# RZN2L register map
Vendor: Renesas Electronics Corporation; Series: RZN; File version: 1.30.01
CPU: other r0p0, little endian, MPU, no FPU, VTOR, 4 interrupt priority bits, 624 interrupts
Registers are 32-bit, read-write, reset 0x0 unless marked. A register's access mark holds for its fields unless they carry their own. Offsets are from the block's base; [hi:lo] are bit positions; {n}, {i} and the like mark numbered series; 'fields as' and 'values as' point back to an identical list.

## XSPI0 — xSPI
Base 0x80220000
Same registers: XSPI1 0x80221000
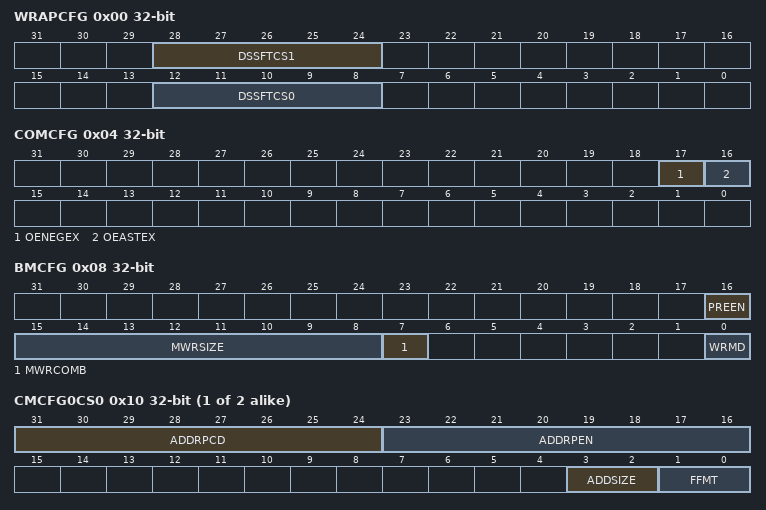
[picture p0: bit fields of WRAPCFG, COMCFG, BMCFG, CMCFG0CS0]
0x00 WRAPCFG — xSPI Wrapper Configuration Register
  [28:24] DSSFTCS1 — DS shift for slave1
  [12:8] DSSFTCS0 — DS shift for slave0
0x04 COMCFG — xSPI Common Configuration Register
  [17] OENEGEX — Output Enable Negating extension
    0=No extend 1 cycle Output enable; 1=Extend 1 cycle Output enable
  [16] OEASTEX — Output Enable Asserting extension
    values as OENEGEX
0x08 BMCFG — xSPI Bridge Map Configuration Register
  [16] PREEN — Prefetch enable
    0=Disable prefetch function; 1=Enable prefetch function
  [15:8] MWRSIZE — Memory Write Size
  [7] MWRCOMB — Memory Write Combination mode
    0=Disable combination mode; 1=Enable combination mode
  [0] WRMD — AHB Write Response mode
    0=Return response after storing to Internal Write Buffer; 1=Return response after issuing write transaction to xSPI bus
{0x10+0x10*i} CMCFG0CS{i} (i=0..1) — xSPI Command Map Configuration Register 0 CSn
  [31:24] ADDRPCD — Address Replace Code
  [23:16] ADDRPEN — Address Replace Enable
    0=No replacement (xSPI frame address field is same as AHB address); 1=Replacement
  [3:2] ADDSIZE — Address size
    0=1 byte (256-byte address space); 1=2 bytes (64 KB address space); 2=3 bytes (16 MB address space); 3=4 bytes (4 GB address space)
  [1:0] FFMT — Frame format
    0=Normal format: Command 1 byte, Address ADDSIZE, Data to AHB transaction; 1=8D-8D-8D profile 1.0 format: Command 2 bytes, Address ADDSIZE, Data to AHB transaction; 2=8D-8D-8D profile 2.0 Command Modifier format: Command & Modifier 6 bytes, Data to AHB transaction; 3=8D-8D-8D profile 2.0 Commands with Extended Command Modifier format: Command & Modifier 6 bytes, Data to AHB transaction
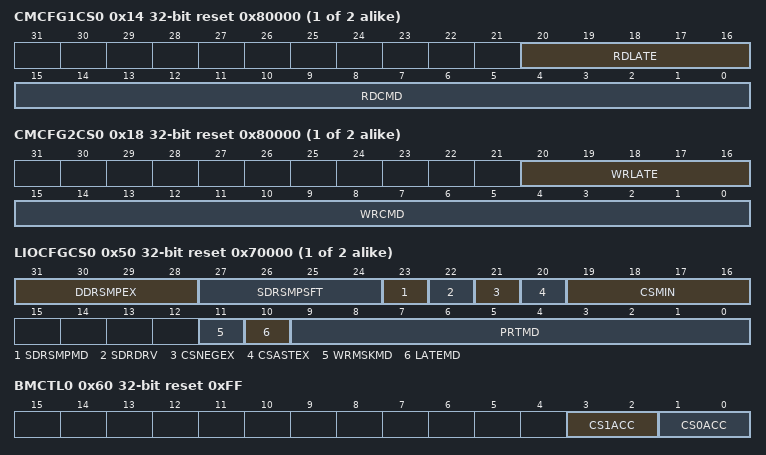
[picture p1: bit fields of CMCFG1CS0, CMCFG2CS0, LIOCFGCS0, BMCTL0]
{0x14+0x10*i} CMCFG1CS{i} (i=0..1) reset 0x80000 — xSPI Command Map Configuration Register 1 CSn
  [20:16] RDLATE — Read latency cycle
  [15:0] RDCMD — Read command
{0x18+0x10*i} CMCFG2CS{i} (i=0..1) reset 0x80000 — xSPI Command Map Configuration Register 2 CSn
  [20:16] WRLATE — Write latency cycle
  [15:0] WRCMD — Write command
{0x50+4i} LIOCFGCS{i} (i=0..1) reset 0x70000 — xSPI Link I/O Configuration Register CSn
  [31:28] DDRSMPEX — DDR sampling window extend
  [27:24] SDRSMPSFT — SDR Sampling window shift
  [23] SDRSMPMD — SDR Sampling mode
    0=Samples data input at falling-edge; 1=Samples data input at rising-edge
  [22] SDRDRV — SDR driving timing
    0=Drive at 1/2 cycle before CK rising-edge; 1=Drive at CK rising-edge
  [21] CSNEGEX — CS negating extension
    0=No extension; 1=Extend 1 cycle
  [20] CSASTEX — CS asserting extension
    0=No extension; 1=Extend 1 cycle
  [19:16] CSMIN — CS minimum idle term
  [11] WRMSKMD — Write mask mode
    0=Write mask disable; 1=Write mask enable
  [10] LATEMD — Latency mode
  [9:0] PRTMD — Protocol mode
    0=1S-1S-1S; 0x3B2=4S-4D-4D; 0x3FF=8D-8D-8D; 72=1S-2S-2S; 73=2S-2S-2S; 144=1S-4S-4S; 146=4S-4S-4S; other=Others (Setting prohibited)
0x60 BMCTL0 reset 0xFF — xSPI Bridge Map Control Register 0
  [3:2] CS1ACC — AHB channel to slave1 memory area access enable
    0=Read/Write disable; 1=Read enable, Write disable; 2=Read disable, Write enable; 3=Read/Write enable
  [1:0] CS0ACC — AHB channel to slave0 memory area access enable
    values as CS1ACC
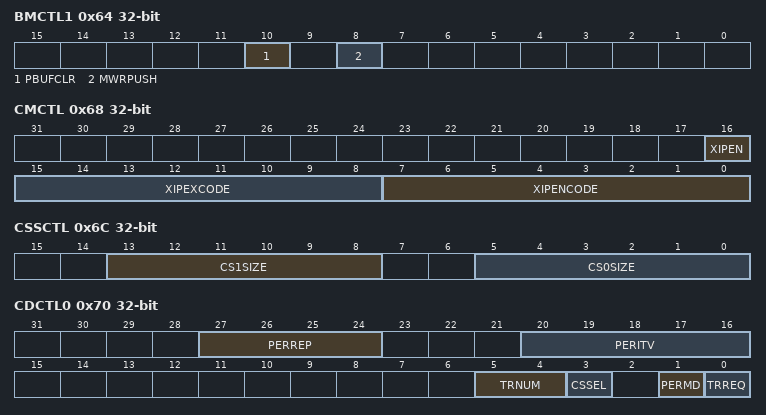
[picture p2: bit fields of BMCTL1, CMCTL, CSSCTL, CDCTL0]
0x64 BMCTL1 wo — xSPI Bridge Map Control Register 1
  [10] PBUFCLR — Prefetch Buffer clear
    0=No command; 1=Clear request
  [8] MWRPUSH — Memory Write Data Push
    0=No command; 1=Push request
0x68 CMCTL — xSPI Command Map Control Register
  [16] XIPEN — XiP mode enable
    0=Disable XiP mode; 1=Enable XiP mode
  [15:8] XIPEXCODE — XiP mode exit code
  [7:0] XIPENCODE — XiP mode enter code
0x6C CSSCTL — xSPI CS Size Control Register
  [13:8] CS1SIZE — CS1 (slave1) size
    0=1 MB; 1=2 MB; 3=4 MB; 7=8 MB; 15=16 MB; 31=32 MB; 63=64 MB; other=Others (Setting prohibited)
  [5:0] CS0SIZE — CS0 (slave0) size
    values as CS1SIZE
0x70 CDCTL0 — xSPI Command Manual Control Register 0
  [27:24] PERREP — Periodic transaction repeat
  [20:16] PERITV — Periodic transaction interval
  [5:4] TRNUM — Transaction number
    0=Issue 1 command (using command buffer 0); 1=Issue 2 commands (using command buffer 0-1); 2=Issue 3 commands (using command buffer 0-2); 3=Issue 4 commands (using command buffer 0-3)
  [3] CSSEL — Chip select
    0=CS0; 1=CS1
  [1] PERMD — Periodic mode
    0=Direct manual-command mode; 1=Periodic manual-command mode
  [0] TRREQ — Transaction request
    0=No transaction; 1=Request transaction
0x74 CDCTL1 — xSPI Command Manual Control Register 1
  [31:0] PEREXP — Periodic transaction expected value
0x78 CDCTL2 — xSPI Command Manual Control Register 2
  [31:0] PERMSK — Periodic transaction masked value
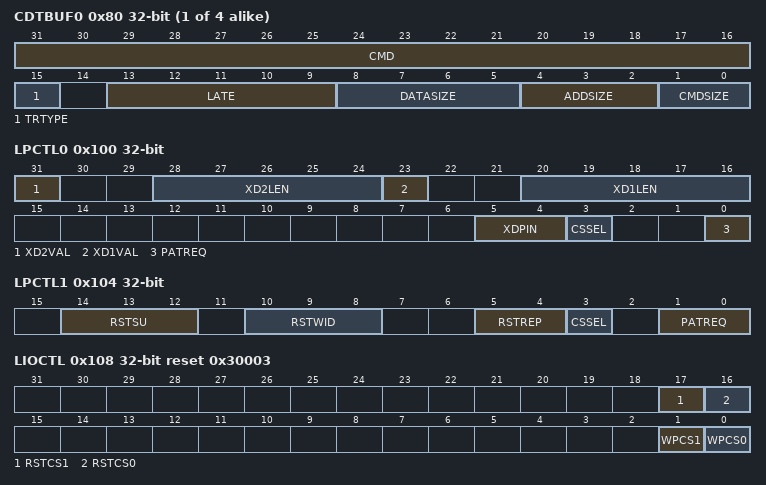
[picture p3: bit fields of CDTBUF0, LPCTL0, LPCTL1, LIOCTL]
{0x80+0x10*i} CDTBUF{i} (i=0..3) — xSPI Command Manual Type Buf {i}
  [31:16] CMD — Command (1-2 bytes)
  [15] TRTYPE — Transaction Type
    0=Read transaction (Readout data from slave device); 1=Not read transaction
  [13:9] LATE — Latency cycle
  [8:5] DATASIZE — Write/Read Data Size
  [4:2] ADDSIZE — Address size
    0=0 bytes (No address phase); 1=1 byte; 2=2 bytes; 3=3 bytes; 4=4 bytes; other=Others (Setting prohibited)
  [1:0] CMDSIZE — Command Size
    0=0 bytes (No command phase); 1=1 byte; 2=2 bytes; other=Others (Setting prohibited)
{0x84+0x10*i} CDABUF{i} (i=0..3) — xSPI Command Manual Address Buf {i}
  [31:0] ADD — Address
{0x88+0x10*i} CDD0BUF{i} (i=0..3) — xSPI Command Manual Data 0 Buf {i}
  [31:0] DATA — Write/Read Data
{0x8C+0x10*i} CDD1BUF{i} (i=0..3) — xSPI Command Manual Data 1 Buf {i}
  [31:0] DATA — Write/Read Data
0x100 LPCTL0 — xSPI Link Pattern Control Register 0
  [31] XD2VAL — XiP Disable pattern 2nd phase value
    0=Low drive; 1=High drive
  [28:24] XD2LEN — XiP Disable pattern 2nd phase length
  [23] XD1VAL — XiP Disable pattern 1st phase value
    0=Low drive; 1=High drive
  [20:16] XD1LEN — XiP Disable pattern 1st phase length
  [5:4] XDPIN — XiP Disable pattern pin
    0=1 pin; 1=2 pins; 2=4 pins; 3=8 pins
  [3] CSSEL — Chip select
    0=slave0 (CS0); 1=slave1 (CS1)
  [0] PATREQ — Pattern request
    0=No request XiP Disable pattern; 1=Request XiP Disable pattern
0x104 LPCTL1 — xSPI Link Pattern Control Register 1
  [14:12] RSTSU — Reset pattern data output setup time
  [10:8] RSTWID — Reset pattern width
  [5:4] RSTREP — Reset pattern repeat
    0=4 times (Specified on Reset Signaling Protocol); 1=5 times; 2=6 times; 3=7 times
  [3] CSSEL — Chip select
    0=slave0 (CS0); 1=slave1 (CS1)
  [1:0] PATREQ — Pattern request
    0=No request; 1=Request Reset pattern; 2=Request CS only pattern; 3=Setting prohibited
0x108 LIOCTL reset 0x30003 — xSPI Link I/O Control Register
  [all] fields
    0=Drive Low level; 1=Drive High level
  [17] RSTCS1 — Reset drive for slave1
  [16] RSTCS0 — Reset drive for slave0
  [1] WPCS1 — WP drive for slave1
  [0] WPCS0 — WP drive for slave0
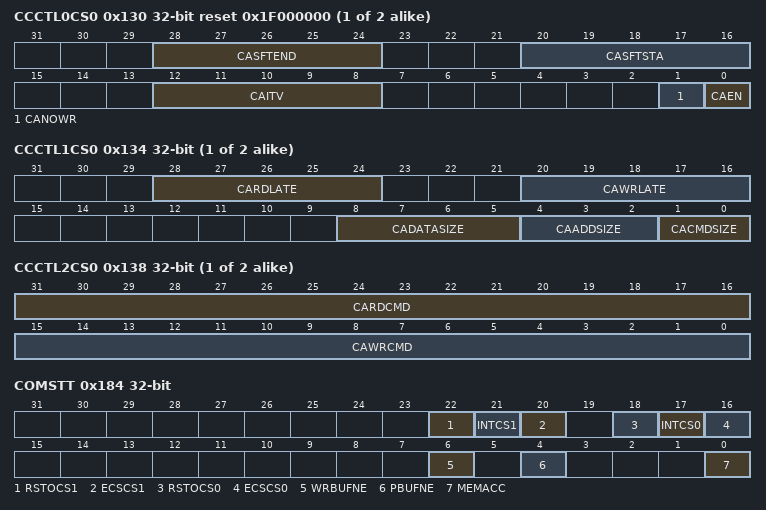
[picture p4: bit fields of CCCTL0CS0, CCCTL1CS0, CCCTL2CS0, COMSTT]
{0x130+0x20*i} CCCTL0CS{i} (i=0..1) reset 0x1F000000 — xSPI Command Calibration Control Register 0 CSn
  [28:24] CASFTEND — Calibration DS shift end value
  [20:16] CASFTSTA — Calibration DS shift start value
  [12:8] CAITV — Calibration interval
  [1] CANOWR — Calibration no write mode
    0=Calibration sequence with write command; 1=Calibration sequence without write command
  [0] CAEN — Automatic Calibration Enable
    0=Disable automatic calibration; 1=Enable automatic calibration
{0x134+0x20*i} CCCTL1CS{i} (i=0..1) — xSPI Command Calibration Control Register 1 CSn
  [28:24] CARDLATE — Read Latency cycle
  [20:16] CAWRLATE — Write Latency cycle
  [8:5] CADATASIZE — Write/Read Data Size
  [4:2] CAADDSIZE — Address size
    values as CDTBUF0.ADDSIZE
  [1:0] CACMDSIZE — Command Size
    0=0 bytes (No command phase); 1=1 byte; 2=2 bytes; 3=Setting prohibited
{0x138+0x20*i} CCCTL2CS{i} (i=0..1) — xSPI Command Calibration Control Register 2 CSn
  [31:16] CARDCMD — Calibration pattern read command
  [15:0] CAWRCMD — Calibration pattern write command
{0x13C+0x20*i} CCCTL3CS{i} (i=0..1) — xSPI Command Calibration Control Register 3 CSn
  [31:0] CAADD — Calibration pattern address
{0x140+0x20*i} CCCTL4CS{i} (i=0..1) — xSPI Command Calibration Control Register 4 CSn
  [31:0] CADATA — Calibration pattern data
{0x144+0x20*i} CCCTL5CS{i} (i=0..1) — xSPI Command Calibration Control Register 5 CSn
  [31:0] CADATA — Calibration pattern data
{0x148+0x20*i} CCCTL6CS{i} (i=0..1) — xSPI Command Calibration Control Register 6 CSn
  [31:0] CADATA — Calibration pattern data
{0x14C+0x20*i} CCCTL7CS{i} (i=0..1) — xSPI Command Calibration Control Register 7 CSn
  [31:0] CADATA — Calibration pattern data
0x180 VERSTT ro — xSPI Version Register
  [31:0] VER — Version
0x184 COMSTT ro (reset mask 0xFF8FFFFF) — xSPI Common Status Register
  [22] RSTOCS1 — RSTO monitor for slave1
    0=Low level; 1=High level
  [21] INTCS1 — INT monitor for slave1
    0=Low level; 1=High level
  [20] ECSCS1 — ECS monitor for slave1
    0=Low level; 1=High level
  [18] RSTOCS0 — RSTO monitor for slave0
    0=Low level; 1=High level
  [17] INTCS0 — INT monitor for slave0
    0=Low level; 1=High level
  [16] ECSCS0 — ECS monitor for slave0
    0=Low level; 1=High level
  [6] WRBUFNE — Write Buffer Not Empty
    0=Empty; 1=Not empty
  [4] PBUFNE — Prefetch Buffer Not Empty
    0=Empty; 1=Not empty
  [0] MEMACC — Memory access ongoing
    0=AHB channel is not accessing to memory; 1=AHB channel is accessing to memory
{0x188+4i} CASTTCS{i} (i=0..1) ro — xSPI Calibration Status Register CSn
  [31:0] CASUC — Calibration Success
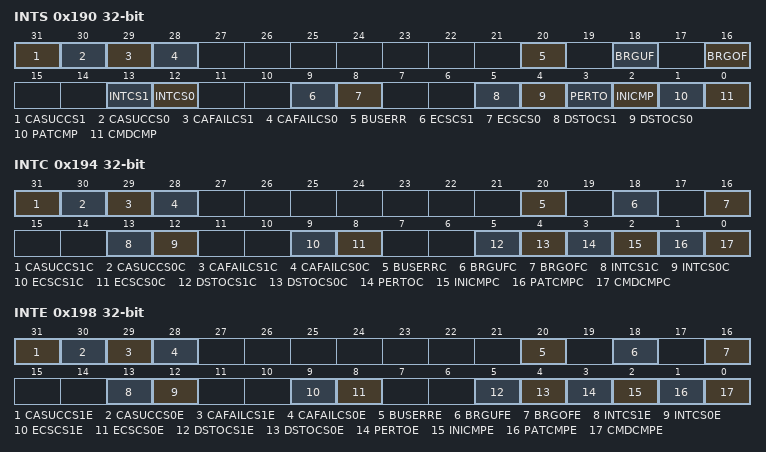
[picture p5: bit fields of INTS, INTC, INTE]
0x190 INTS ro (reset mask 0xFFFFCCFF) — xSPI Interrupt Status Register
  [31] CASUCCS1 — Calibration success for slave1
    0=No detection; 1=Detection
  [30] CASUCCS0 — Calibration success for slave0
    0=No detection; 1=Detection
  [29] CAFAILCS1 — Calibration failed for slave1
    0=No detection; 1=Detection
  [28] CAFAILCS0 — Calibration failed for slave0
    0=No detection; 1=Detection
  [20] BUSERR — AHB bus error
  [18] BRGUF — Bridge Buffer underflow
  [16] BRGOF — Bridge Buffer overflow
  [13] INTCS1 — Interrupt detection for slave1
    0=No detection; 1=Detection
  [12] INTCS0 — Interrupt detection for slave0
    0=No detection; 1=Detection
  [9] ECSCS1 — ECC error detection for slave1
    0=No detection; 1=Detection
  [8] ECSCS0 — ECC error detection for slave0
    0=No detection; 1=Detection
  [5] DSTOCS1 — DS timeout for slave1
    0=No detection; 1=Detection
  [4] DSTOCS0 — DS timeout for slave0
    0=No detection; 1=Detection
  [3] PERTO — Periodic transaction timeout
    0=No detection; 1=Detection
  [2] INICMP — Initial Sequence Completed
    0=No detection; 1=Detection
  [1] PATCMP — Pattern Completed
    0=No detection; 1=Detection
  [0] CMDCMP — Command Completed
    0=No detection; 1=Detection
0x194 INTC wo — xSPI Interrupt Clear Register
  [all] fields
    0=No change interrupt status; 1=Clear interrupt status
  [31] CASUCCS1C — Calibration success for slave1 interrupt clear
  [30] CASUCCS0C — Calibration success for slave0 interrupt clear
  [29] CAFAILCS1C — Calibration failed for slave1 interrupt clear
  [28] CAFAILCS0C — Calibration failed for slave0 interrupt clear
  [20] BUSERRC — AHB bus error interrupt clear
  [18] BRGUFC — Bridge Buffer underflow interrupt clear
  [16] BRGOFC — Bridge Buffer overflow interrupt clear
  [13] INTCS1C — Interrupt detection for slave1 interrupt clear
  [12] INTCS0C — Interrupt detection for slave0 interrupt clear
  [9] ECSCS1C — ECC error detection for slave1 interrupt clear
  [8] ECSCS0C — ECC error detection for slave0 interrupt clear
  [5] DSTOCS1C — DS timeout for slave1 interrupt clear
  [4] DSTOCS0C — DS timeout for slave0 interrupt clear
  [3] PERTOC — Periodic transaction timeout interrupt clear
  [2] INICMPC — Initial Sequence Completed interrupt clear
  [1] PATCMPC — Pattern Completed interrupt clear
  [0] CMDCMPC — Command Completed interrupt clear
0x198 INTE — xSPI Interrupt Enable Register
  [all] fields
    0=Disabled; 1=Enabled
  [31] CASUCCS1E — Calibration success for slave1 interrupt enable
  [30] CASUCCS0E — Calibration success for slave0 interrupt enable
  [29] CAFAILCS1E — Calibration failed for slave1 interrupt enable
  [28] CAFAILCS0E — Calibration failed for slave0 interrupt enable
  [20] BUSERRE — AHB bus error interrupt enable
  [18] BRGUFE — Bridge Buffer underflow interrupt enable
  [16] BRGOFE — Bridge Buffer overflow interrupt enable
  [13] INTCS1E — Interrupt detection for slave1 interrupt enable
  [12] INTCS0E — Interrupt detection for slave0 interrupt enable
  [9] ECSCS1E — ECC error detection for slave1 interrupt enable
  [8] ECSCS0E — ECC error detection for slave0 interrupt enable
  [5] DSTOCS1E — DS timeout for slave1 interrupt enable
  [4] DSTOCS0E — DS timeout for slave0 interrupt enable
  [3] PERTOE — Periodic transaction timeout interrupt enable
  [2] INICMPE — Initial Sequence Completed interrupt enable
  [1] PATCMPE — Pattern Completed interrupt enable
  [0] CMDCMPE — Command Completed interrupt enable
